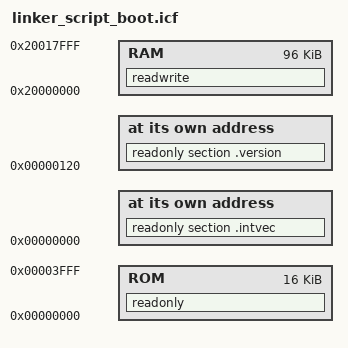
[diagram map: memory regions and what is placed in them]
/*****************************************************************************
*
* © 2014 Cyber-SB. Written by Selyutin Alex.
*
*****************************************************************************/

define memory MEM with size = 4G; // Global memory address space

define region ROM = MEM:[from 0x00000000 size 0x4000];  // 16 KiB, for boot loader. See mem_map.h file.
define region RAM = MEM:[from 0x20000000 size 0x18000]; // 96 KiB

place in ROM { readonly };
place in RAM { readwrite };

//initialize by copy with packing = smallest { readwrite };
//initialize by copy with packing = lzw { readwrite };

initialize by copy { readwrite };
do not initialize  { section .noinit };

place at address MEM:0x00000000 { readonly section .intvec };
place at address MEM:0x00000120 { readonly section .version };
